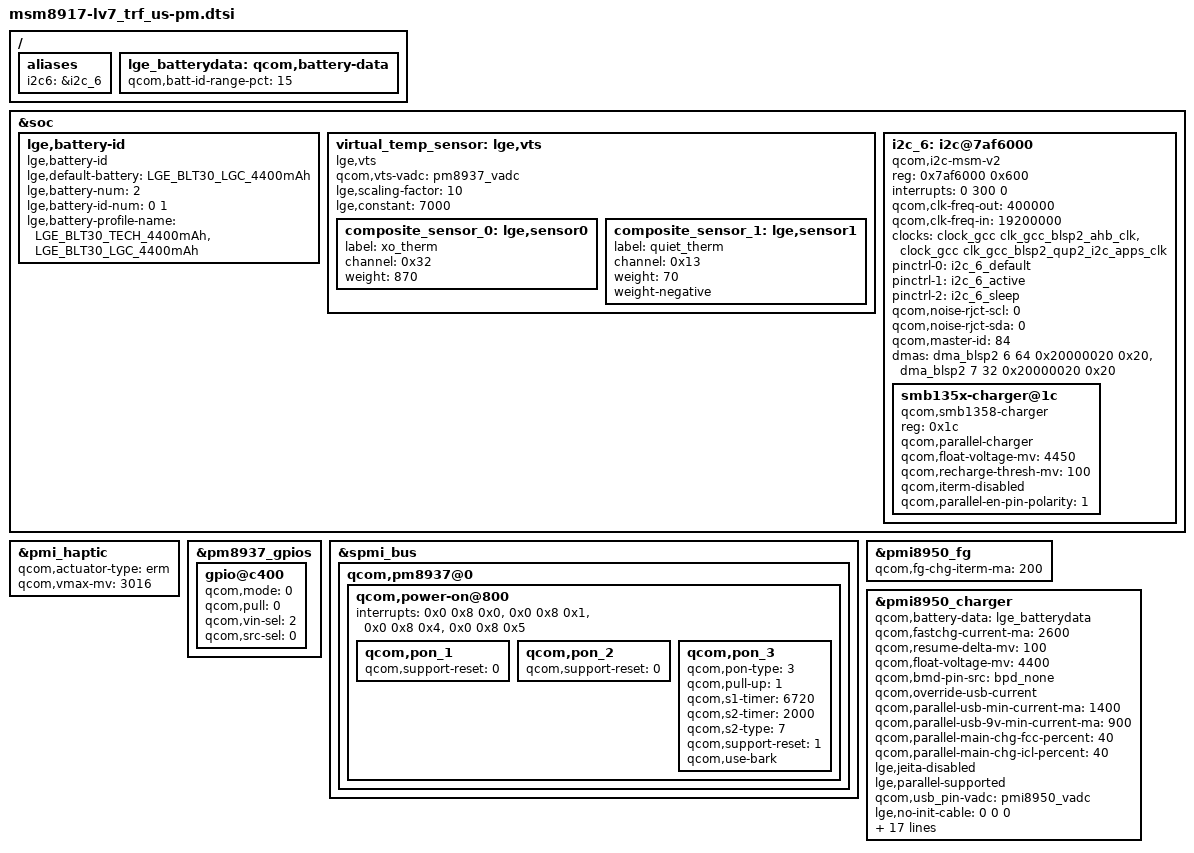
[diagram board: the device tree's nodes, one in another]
/*
 * Copyright (c) 2016, The Linux Foundation. All rights reserved.
 *
 * This program is free software; you can redistribute it and/or modify
 * it under the terms of the GNU General Public License version 2 and
 * only version 2 as published by the Free Software Foundation.
 *
 * This program is distributed in the hope that it will be useful,
 * but WITHOUT ANY WARRANTY; without even the implied warranty of
 * MERCHANTABILITY or FITNESS FOR A PARTICULAR PURPOSE.  See the
 * GNU General Public License for more details.
 */

/ {
	aliases {
		i2c6 = &i2c_6;
	};
};

/{
	lge_batterydata: qcom,battery-data {
		qcom,batt-id-range-pct = <15>;
		#include "../battery_profile/LGE_BLT30_LGC_4400mAh.dtsi"
		#include "../battery_profile/LGE_BLT30_TECH_4400mAh.dtsi"
	};
};

&soc {
	lge,battery-id{
		compatible = "lge,battery-id";
		/delete-property/ lge,restrict-mode-enabled;
		/*default battery profile*/
		lge,default-battery = "LGE_BLT30_LGC_4400mAh";
		/*Total number of combined of battery cell and battery id */
		lge,battery-num = <2>;
		/* battery id and battery profile match numbers */
		lge,battery-id-num = <0 1>;
		/* battery profile */
		lge,battery-profile-name = "LGE_BLT30_TECH_4400mAh",
						"LGE_BLT30_LGC_4400mAh";
	};

	/* vts = (0.87*xo_therm) + (-0.07*quiet_therm) + 7.0 */
	virtual_temp_sensor: lge,vts {
		compatible = "lge,vts";
		qcom,vts-vadc = <&pm8937_vadc>;
		lge,scaling-factor= <10>;
		lge,constant = <7000>;
		composite_sensor_0: lge,sensor0 {
			label = "xo_therm";
			channel = <0x32>;
			weight = <870>;
		};
		composite_sensor_1: lge,sensor1 {
			label = "quiet_therm";
			channel = <0x13>;
			weight = <70>;
			weight-negative;
		};
	};

	i2c_6: i2c@7af6000 { /* BLSP2 QUP2 */
		compatible = "qcom,i2c-msm-v2";
		#address-cells = <1>;
		#size-cells = <0>;
		reg-names = "qup_phys_addr";
		reg = <0x7af6000 0x600>;
		interrupt-names = "qup_irq";
		interrupts = <0 300 0>;
		qcom,clk-freq-out = <400000>;
		qcom,clk-freq-in  = <19200000>;
		clock-names = "iface_clk", "core_clk";
		clocks = <&clock_gcc clk_gcc_blsp2_ahb_clk>,
			 <&clock_gcc clk_gcc_blsp2_qup2_i2c_apps_clk>;

		pinctrl-names = "default", "i2c_active", "i2c_sleep";
		pinctrl-0 = <&i2c_6_default>;
		pinctrl-1 = <&i2c_6_active>;
		pinctrl-2 = <&i2c_6_sleep>;
		qcom,noise-rjct-scl = <0>;
		qcom,noise-rjct-sda = <0>;
		qcom,master-id = <84>;
		dmas = <&dma_blsp2 6 64 0x20000020 0x20>,
			<&dma_blsp2 7 32 0x20000020 0x20>;
		dma-names = "tx", "rx";
	};
};

&pmi_haptic{
	status = "okay";
	qcom,actuator-type = "erm";
	qcom,vmax-mv = <3016>;
};

&pm8937_gpios {
	gpio@c400 {
		qcom,mode = <0>;
		qcom,pull = <0>;
		qcom,vin-sel = <2>;
		qcom,src-sel = <0>;
		status = "okay";
	};
};

&spmi_bus {
	qcom,pm8937@0 {
		qcom,power-on@800 {
			interrupts = <0x0 0x8 0x0>,
				     <0x0 0x8 0x1>,
				     <0x0 0x8 0x4>,
				     <0x0 0x8 0x5>;
			interrupt-names = "kpdpwr", "resin",
				"resin-bark", "kpdpwr-resin-bark";

			qcom,pon_1 {
				status = "ok";
				qcom,support-reset = <0>;
			};
			qcom,pon_2 {
				status = "ok";
				qcom,support-reset = <0>;
			};
			qcom,pon_3 {
				status = "ok";
				qcom,pon-type = <3>;
				qcom,pull-up = <1>;
				qcom,s1-timer = <6720>;
				qcom,s2-timer = <2000>;
				qcom,s2-type = <7>;
				qcom,support-reset = <1>;
				qcom,use-bark;
			};
		};
	};
};

&pmi8950_fg {
	qcom,fg-chg-iterm-ma = <200>;
};

&pmi8950_charger {
	qcom,battery-data = <&lge_batterydata>;
	qcom,fastchg-current-ma = <2600>;
	qcom,resume-delta-mv = <100>;
	qcom,float-voltage-mv = <4400>;
	qcom,bmd-pin-src = "bpd_none";
	qcom,override-usb-current;
	qcom,parallel-usb-min-current-ma = <1400>;
	qcom,parallel-usb-9v-min-current-ma = <900>;
	qcom,parallel-main-chg-fcc-percent = <40>;
	qcom,parallel-main-chg-icl-percent = <40>;
	lge,jeita-disabled;
	lge,parallel-supported;

	qcom,usb_pin-vadc = <&pmi8950_vadc>;

	/* ref resistance 200K */
	lge,no-init-cable = <0 0 0>;
	lge,cable-mhl-1k = <5000 500 500>;
	lge,cable-u-28p7k = <10000 1800 500>;
	lge,cable-28p7k = <250000 1800 500>;
	lge,cable-56k = <600000 1800 1500>;
	lge,cable-100k = <620000 1800 500>;
	lge,cable-130k = <780000 1800 1500>;
	lge,cable-180k = <870000 1800 500>;
	lge,cable-200k = <910000 1800 500>;
	lge,cable-220k = <960000 1800 500>;
	lge,cable-270k = <1050000 1800 500>;
	lge,cable-330k = <1150000 1800 500>;
	lge,cable-620k = <1380000 1800 500>;
	lge,cable-910k = <1630000 1800 1500>;
	lge,cable-none = <1900000 1800  500>;

	lge,usb-max-current-ma = <1800>;
	lge,iusb-qc20 = <1800 1800>;
	lge,ibat-qc20 = <2600 1000>;
};

&i2c_6 {
	/* Parallel-charger configuration */
	smb135x-charger@1c{
		compatible = "qcom,smb1358-charger";
		reg = <0x1c>;
		qcom,parallel-charger;
		qcom,float-voltage-mv = <4450>;
		qcom,recharge-thresh-mv = <100>;
		qcom,iterm-disabled;
		qcom,parallel-en-pin-polarity = <1>;
	};
};
